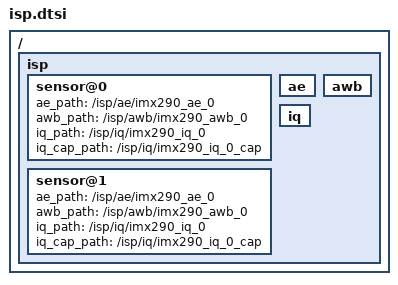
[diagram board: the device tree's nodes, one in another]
/ {
	isp {
		sensor@0 {
			ae_path                 = "/isp/ae/imx290_ae_0";
			awb_path                = "/isp/awb/imx290_awb_0";
			iq_path                 = "/isp/iq/imx290_iq_0";
			iq_cap_path				= "/isp/iq/imx290_iq_0_cap";
		};
		sensor@1 {
			ae_path                 = "/isp/ae/imx290_ae_0";
			awb_path                = "/isp/awb/imx290_awb_0";
			iq_path                 = "/isp/iq/imx290_iq_0";
			iq_cap_path				= "/isp/iq/imx290_iq_0_cap";
		};
		/* label for ae, awb, iq table */
		ae: ae {
		};
		awb: awb {
		};
		iq: iq {
		};
	};
};

/* Note: put include files in the tail since label should be declared first. */
#include "imx290_ae_0.dtsi"
#include "imx290_awb_0.dtsi"
#include "imx290_iq_0.dtsi"
#include "imx290_iq_0_cap.dtsi"

